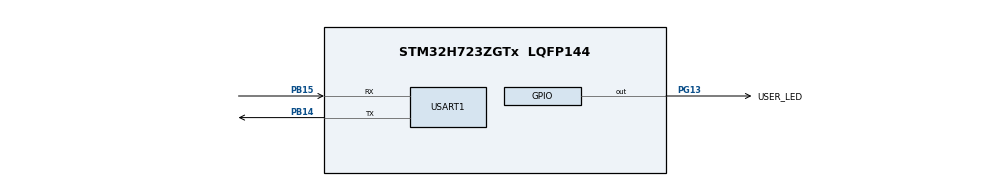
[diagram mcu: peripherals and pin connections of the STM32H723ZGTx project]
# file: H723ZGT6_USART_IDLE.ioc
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CORTEX_M7.AccessPermission-Cortex_Memory_Protection_Unit_Region0_Settings=MPU_REGION_FULL_ACCESS
CORTEX_M7.AccessPermission-Cortex_Memory_Protection_Unit_Region1_Settings=MPU_REGION_FULL_ACCESS
CORTEX_M7.BaseAddress-Cortex_Memory_Protection_Unit_Region0_Settings=0x24000000
CORTEX_M7.BaseAddress-Cortex_Memory_Protection_Unit_Region1_Settings=0x24040000
CORTEX_M7.CPU_DCache=Enabled
CORTEX_M7.CPU_ICache=Enabled
CORTEX_M7.Enable-Cortex_Memory_Protection_Unit_Region0_Settings=MPU_REGION_ENABLE
CORTEX_M7.Enable-Cortex_Memory_Protection_Unit_Region1_Settings=MPU_REGION_ENABLE
CORTEX_M7.IsCacheable-Cortex_Memory_Protection_Unit_Region0_Settings=MPU_ACCESS_CACHEABLE
CORTEX_M7.IsCacheable-Cortex_Memory_Protection_Unit_Region1_Settings=MPU_ACCESS_CACHEABLE
CORTEX_M7.MPU_Control=MPU_PRIVILEGED_DEFAULT
CORTEX_M7.Size-Cortex_Memory_Protection_Unit_Region0_Settings=MPU_REGION_SIZE_256KB
CORTEX_M7.Size-Cortex_Memory_Protection_Unit_Region1_Settings=MPU_REGION_SIZE_64KB
Dma.Request0=USART1_RX
Dma.USART1_RX.0.Direction=DMA_PERIPH_TO_MEMORY
Dma.USART1_RX.0.EventEnable=DISABLE
Dma.USART1_RX.0.FIFOMode=DMA_FIFOMODE_DISABLE
Dma.USART1_RX.0.Instance=DMA1_Stream0
Dma.USART1_RX.0.MemDataAlignment=DMA_MDATAALIGN_BYTE
Dma.USART1_RX.0.MemInc=DMA_MINC_ENABLE
Dma.USART1_RX.0.Mode=DMA_NORMAL
Dma.USART1_RX.0.PeriphDataAlignment=DMA_PDATAALIGN_BYTE
Dma.USART1_RX.0.PeriphInc=DMA_PINC_DISABLE
Dma.USART1_RX.0.Polarity=HAL_DMAMUX_REQ_GEN_RISING
Dma.USART1_RX.0.Priority=DMA_PRIORITY_HIGH
Dma.USART1_RX.0.RequestNumber=1
Dma.USART1_RX.0.SignalID=NONE
Dma.USART1_RX.0.SyncEnable=DISABLE
Dma.USART1_RX.0.SyncPolarity=HAL_DMAMUX_SYNC_NO_EVENT
Dma.USART1_RX.0.SyncRequestNumber=1
Dma.USART1_RX.0.SyncSignalID=NONE
Mcu.Family=STM32H7
Mcu.Name=STM32H723ZGTx
Mcu.Package=LQFP144
NVIC.DMA1_Stream0_IRQn=true\:0\:0\:false\:false\:true\:false\:true\:true
NVIC.PriorityGroup=NVIC_PRIORITYGROUP_4
NVIC.USART1_IRQn=true\:1\:0\:true\:false\:true\:true\:true\:true
PB14.GPIO_Speed=GPIO_SPEED_FREQ_VERY_HIGH
PB14.Mode=Asynchronous
PB14.Signal=USART1_TX
PB15.GPIO_Speed=GPIO_SPEED_FREQ_VERY_HIGH
PB15.Mode=Asynchronous
PB15.Signal=USART1_RX
PG13.GPIO_Label=USER_LED
PG13.PinState=GPIO_PIN_SET
PG13.Signal=GPIO_Output
PH0-OSC_IN.Mode=HSE-External-Oscillator
PH0-OSC_IN.Signal=RCC_OSC_IN
PH1-OSC_OUT.Mode=HSE-External-Oscillator
PH1-OSC_OUT.Signal=RCC_OSC_OUT
ProjectManager.HeapSize=0x2000
ProjectManager.StackSize=0x3000
ProjectManager.TargetToolchain=MDK-ARM V5.32
RCC.ADCFreq_Value=50390625
RCC.APB1Freq_Value=137500000
RCC.APB2Freq_Value=137500000
RCC.APB3Freq_Value=137500000
RCC.APB4Freq_Value=137500000
RCC.CortexFreq_Value=550000000
RCC.D1PPRE=RCC_APB3_DIV2
RCC.D2PPRE1=RCC_APB1_DIV2
RCC.D2PPRE2=RCC_APB2_DIV2
RCC.D3PPRE=RCC_APB4_DIV2
RCC.DIVM1=2
RCC.DIVN1=44
RCC.DIVP1=1
RCC.HCLKFreq_Value=275000000
RCC.HPRE=RCC_HCLK_DIV2
RCC.PLLSourceVirtual=RCC_PLLSOURCE_HSE
RCC.SYSCLKFreq_VALUE=550000000
RCC.SYSCLKSource=RCC_SYSCLKSOURCE_PLLCLK
RCC.USBFreq_Value=275000000
USART1.VirtualMode-Asynchronous=VM_ASYNC
board=custom

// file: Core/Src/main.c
/* USER CODE BEGIN Header */
/**
  ******************************************************************************
  * @file           : main.c
  * @brief          : Main program body
  ******************************************************************************
  * @attention
  *
  * Copyright (c) 2024 STMicroelectronics.
  * All rights reserved.
  *
  * This software is licensed under terms that can be found in the LICENSE file
  * in the root directory of this software component.
  * If no LICENSE file comes with this software, it is provided AS-IS.
  *
  ******************************************************************************
  */
/* USER CODE END Header */
#include "main.h"
#include "dma.h"
#include "usart.h"
#include "gpio.h"

/* USER CODE BEGIN Includes */
#include <stdio.h>
#include <string.h>
#include "uart_command.h"
/* USER CODE END Includes */

/* USER CODE BEGIN PV */
extern volatile uint8_t usart1_rx_flag;
extern UART_RXBuffer_Handle uart1_rx_handler;

uint8_t uart_status;
/* USER CODE END PV */

void SystemClock_Config(void);
static void MPU_Config(void);

int main(void)
{

  /* MPU Configuration--------------------------------------------------------*/
  MPU_Config();

  /* Enable the CPU Cache */

  /* Enable I-Cache---------------------------------------------------------*/
  SCB_EnableICache();

  /* Enable D-Cache---------------------------------------------------------*/
  SCB_EnableDCache();

  /* MCU Configuration--------------------------------------------------------*/

  /* Reset of all peripherals, Initializes the Flash interface and the Systick. */
  HAL_Init();

  /* Configure the system clock */
  SystemClock_Config();

  /* Initialize all configured peripherals */
  MX_GPIO_Init();
  MX_DMA_Init();
  MX_USART1_UART_Init();

  /* Infinite loop */
  /* USER CODE BEGIN WHILE */
  while (1)
  {
		if(usart1_rx_flag)
		{
		  usart1_rx_flag = 0;
			SCB_InvalidateDCache_by_Addr((uint32_t *)uart1_rx_handler.rx_buffer,USART_RX_BUFFER_NUM);
			uart_status = Uart_Command_Process((const char *)uart1_rx_handler.rx_buffer);
			USART1_ReceiveIdle_DMA_Start();
		}
    /* USER CODE END WHILE */

  }
}

void SystemClock_Config(void)
{
  RCC_OscInitTypeDef RCC_OscInitStruct = {0};
  RCC_ClkInitTypeDef RCC_ClkInitStruct = {0};

  /** Supply configuration update enable
  */
  HAL_PWREx_ConfigSupply(PWR_LDO_SUPPLY);

  /** Configure the main internal regulator output voltage
  */
  __HAL_PWR_VOLTAGESCALING_CONFIG(PWR_REGULATOR_VOLTAGE_SCALE0);

  while(!__HAL_PWR_GET_FLAG(PWR_FLAG_VOSRDY)) {}

  /** Initializes the RCC Oscillators according to the specified parameters
  * in the RCC_OscInitTypeDef structure.
  */
  RCC_OscInitStruct.OscillatorType = RCC_OSCILLATORTYPE_HSE;
  RCC_OscInitStruct.HSEState = RCC_HSE_ON;
  RCC_OscInitStruct.PLL.PLLState = RCC_PLL_ON;
  RCC_OscInitStruct.PLL.PLLSource = RCC_PLLSOURCE_HSE;
  RCC_OscInitStruct.PLL.PLLM = 2;
  RCC_OscInitStruct.PLL.PLLN = 44;
  RCC_OscInitStruct.PLL.PLLP = 1;
  RCC_OscInitStruct.PLL.PLLQ = 2;
  RCC_OscInitStruct.PLL.PLLR = 2;
  RCC_OscInitStruct.PLL.PLLRGE = RCC_PLL1VCIRANGE_3;
  RCC_OscInitStruct.PLL.PLLVCOSEL = RCC_PLL1VCOWIDE;
  RCC_OscInitStruct.PLL.PLLFRACN = 0;
  if (HAL_RCC_OscConfig(&RCC_OscInitStruct) != HAL_OK)
  {
    Error_Handler();
  }

  /** Initializes the CPU, AHB and APB buses clocks
  */
  RCC_ClkInitStruct.ClockType = RCC_CLOCKTYPE_HCLK|RCC_CLOCKTYPE_SYSCLK
                              |RCC_CLOCKTYPE_PCLK1|RCC_CLOCKTYPE_PCLK2
                              |RCC_CLOCKTYPE_D3PCLK1|RCC_CLOCKTYPE_D1PCLK1;
  RCC_ClkInitStruct.SYSCLKSource = RCC_SYSCLKSOURCE_PLLCLK;
  RCC_ClkInitStruct.SYSCLKDivider = RCC_SYSCLK_DIV1;
  RCC_ClkInitStruct.AHBCLKDivider = RCC_HCLK_DIV2;
  RCC_ClkInitStruct.APB3CLKDivider = RCC_APB3_DIV2;
  RCC_ClkInitStruct.APB1CLKDivider = RCC_APB1_DIV2;
  RCC_ClkInitStruct.APB2CLKDivider = RCC_APB2_DIV2;
  RCC_ClkInitStruct.APB4CLKDivider = RCC_APB4_DIV2;

  if (HAL_RCC_ClockConfig(&RCC_ClkInitStruct, FLASH_LATENCY_3) != HAL_OK)
  {
    Error_Handler();
  }
}

 /* MPU Configuration */

void MPU_Config(void)
{
  MPU_Region_InitTypeDef MPU_InitStruct = {0};

  /* Disables the MPU */
  HAL_MPU_Disable();

  /** Initializes and configures the Region and the memory to be protected
  */
  MPU_InitStruct.Enable = MPU_REGION_ENABLE;
  MPU_InitStruct.Number = MPU_REGION_NUMBER0;
  MPU_InitStruct.BaseAddress = 0x24000000;
  MPU_InitStruct.Size = MPU_REGION_SIZE_256KB;
  MPU_InitStruct.SubRegionDisable = 0x0;
  MPU_InitStruct.TypeExtField = MPU_TEX_LEVEL0;
  MPU_InitStruct.AccessPermission = MPU_REGION_FULL_ACCESS;
  MPU_InitStruct.DisableExec = MPU_INSTRUCTION_ACCESS_ENABLE;
  MPU_InitStruct.IsShareable = MPU_ACCESS_NOT_SHAREABLE;
  MPU_InitStruct.IsCacheable = MPU_ACCESS_CACHEABLE;
  MPU_InitStruct.IsBufferable = MPU_ACCESS_NOT_BUFFERABLE;

  HAL_MPU_ConfigRegion(&MPU_InitStruct);

  /** Initializes and configures the Region and the memory to be protected
  */
  MPU_InitStruct.Number = MPU_REGION_NUMBER1;
  MPU_InitStruct.BaseAddress = 0x24040000;
  MPU_InitStruct.Size = MPU_REGION_SIZE_64KB;

  HAL_MPU_ConfigRegion(&MPU_InitStruct);
  /* Enables the MPU */
  HAL_MPU_Enable(MPU_PRIVILEGED_DEFAULT);

}

void Error_Handler(void)
{
  __disable_irq();
  while (1)
  {
  }
}
